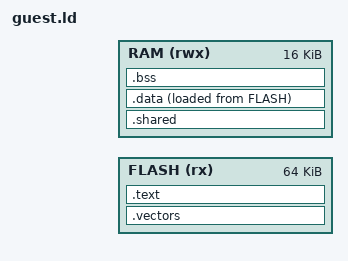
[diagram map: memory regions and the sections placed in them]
/* guest.ld
 *
 * Copyright (C) 2026 wolfSSL Inc.
 *
 * This file is part of wolfTrust.
 *
 * wolfTrust is free software; you can redistribute it and/or modify
 * it under the terms of the GNU General Public License as published by
 * the Free Software Foundation; either version 3 of the License, or
 * (at your option) any later version.
 *
 * wolfTrust is distributed in the hope that it will be useful,
 * but WITHOUT ANY WARRANTY; without even the implied warranty of
 * MERCHANTABILITY or FITNESS FOR A PARTICULAR PURPOSE.  See the
 * GNU General Public License for more details.
 *
 * You should have received a copy of the GNU General Public License
 * along with this program; if not, write to the Free Software
 * Foundation, Inc., 51 Franklin Street, Fifth Floor, Boston, MA 02110-1335, USA
 */

ENTRY(Reset_Handler)

MEMORY {
  FLASH (rx) : ORIGIN = GUEST_FLASH_ORIGIN, LENGTH = 64K
  RAM   (rwx): ORIGIN = GUEST_RAM_ORIGIN, LENGTH = 16K
}

_estack = ORIGIN(RAM) + LENGTH(RAM);
_sidata = LOADADDR(.data);

SECTIONS {
  .shared ORIGIN(RAM) (NOLOAD) : {
    *(.shared*)
  } > RAM

  .vectors GUEST_FLASH_ORIGIN : {
    KEEP(*(.vectors))
  } > FLASH

  .text : {
    *(.text*)
    *(.rodata*)
    *(.ARM.extab* .gnu.linkonce.armextab.*)
    *(.ARM.exidx* .gnu.linkonce.armexidx.*)
  } > FLASH

  .data : {
    _sdata = .;
    *(.data*)
    _edata = .;
  } > RAM AT > FLASH

  .bss (NOLOAD) : {
    _sbss = .;
    *(.bss*)
    *(COMMON)
    _ebss = .;
  } > RAM
}
